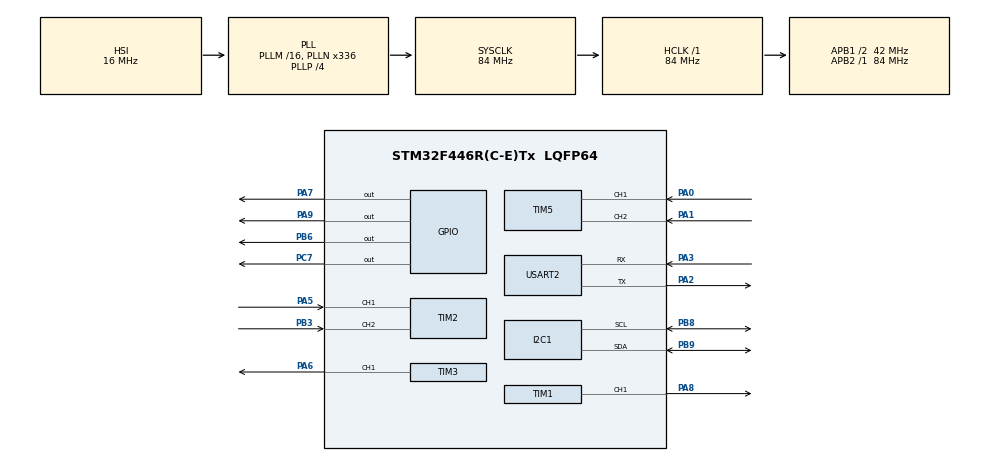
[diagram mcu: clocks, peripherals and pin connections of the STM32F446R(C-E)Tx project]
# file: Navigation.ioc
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Dma.Request0=TIM1_CH1
Dma.TIM1_CH1.0.Direction=DMA_MEMORY_TO_PERIPH
Dma.TIM1_CH1.0.FIFOMode=DMA_FIFOMODE_DISABLE
Dma.TIM1_CH1.0.Instance=DMA2_Stream1
Dma.TIM1_CH1.0.MemDataAlignment=DMA_MDATAALIGN_HALFWORD
Dma.TIM1_CH1.0.MemInc=DMA_MINC_ENABLE
Dma.TIM1_CH1.0.Mode=DMA_NORMAL
Dma.TIM1_CH1.0.PeriphDataAlignment=DMA_PDATAALIGN_HALFWORD
Dma.TIM1_CH1.0.PeriphInc=DMA_PINC_DISABLE
Dma.TIM1_CH1.0.Priority=DMA_PRIORITY_LOW
Mcu.Family=STM32F4
Mcu.Name=STM32F446R(C-E)Tx
Mcu.Package=LQFP64
NVIC.DMA2_Stream1_IRQn=true\:0\:0\:false\:false\:true\:false\:true\:true
NVIC.PriorityGroup=NVIC_PRIORITYGROUP_0
NVIC.TIM2_IRQn=true\:0\:0\:false\:false\:true\:true\:true\:true
NVIC.TIM3_IRQn=true\:0\:0\:false\:false\:true\:true\:true\:true
NVIC.TIM5_IRQn=true\:0\:0\:false\:false\:true\:true\:true\:true
PA0-WKUP.Signal=S_TIM5_CH1
PA1.Signal=S_TIM5_CH2
PA2.Mode=Asynchronous
PA2.Signal=USART2_TX
PA3.Mode=Asynchronous
PA3.Signal=USART2_RX
PA5.Signal=S_TIM2_CH1_ETR
PA6.Signal=S_TIM3_CH1
PA7.Signal=GPIO_Output
PA8.Signal=S_TIM1_CH1
PA9.Signal=GPIO_Output
PB3.Signal=S_TIM2_CH2
PB6.Signal=GPIO_Output
PB8.Mode=I2C
PB8.Signal=I2C1_SCL
PB9.Mode=I2C
PB9.Signal=I2C1_SDA
PC7.Signal=GPIO_Output
ProjectManager.HeapSize=0x200
ProjectManager.StackSize=0x400
ProjectManager.TargetToolchain=STM32CubeIDE
RCC.48MHZClocksFreq_Value=84000000
RCC.AHBFreq_Value=84000000
RCC.APB1CLKDivider=RCC_HCLK_DIV2
RCC.APB1Freq_Value=42000000
RCC.APB1TimFreq_Value=84000000
RCC.APB2Freq_Value=84000000
RCC.APB2TimFreq_Value=84000000
RCC.CortexFreq_Value=84000000
RCC.FLatency-AdvancedSettings=FLASH_LATENCY_2
RCC.HCLKFreq_Value=84000000
RCC.HSE_VALUE=8000000
RCC.HSI_VALUE=16000000
RCC.PLLN=336
RCC.PLLP=RCC_PLLP_DIV4
RCC.SYSCLKFreq_VALUE=84000000
RCC.SYSCLKSource=RCC_SYSCLKSOURCE_PLLCLK
RCC.USBFreq_Value=168000000
RCC.VCOOutputFreq_Value=336000000
SH.S_TIM1_CH1.0=TIM1_CH1,PWM Generation1 CH1
SH.S_TIM2_CH1_ETR.0=TIM2_CH1,Encoder_Interface
SH.S_TIM2_CH2.0=TIM2_CH2,Encoder_Interface
SH.S_TIM3_CH1.0=TIM3_CH1,PWM Generation1 CH1
SH.S_TIM5_CH1.0=TIM5_CH1,Encoder_Interface
SH.S_TIM5_CH2.0=TIM5_CH2,Encoder_Interface
TIM1.Channel-PWM\ Generation1\ CH1=TIM_CHANNEL_1
TIM1.Period=100-1
TIM1.Prescaler=42-1
TIM2.EncoderMode=TIM_ENCODERMODE_TI12
TIM2.IC1Polarity=TIM_ICPOLARITY_FALLING
TIM3.Channel-PWM\ Generation1\ CH1=TIM_CHANNEL_1
TIM3.Period=100-1
TIM3.Prescaler=42-1
TIM5.EncoderMode=TIM_ENCODERMODE_TI12
TIM5.IC2Polarity=TIM_ICPOLARITY_FALLING
USART2.VirtualMode=VM_ASYNC
VP_TIM1_VS_ClockSourceINT.Mode=Internal
VP_TIM3_VS_ClockSourceINT.Mode=Internal
board=NUCLEO-F446RE

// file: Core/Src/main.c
/* USER CODE BEGIN Header */
/**
  ******************************************************************************
  * @file           : main.c
  * @brief          : Main program body
  ******************************************************************************
  * @attention
  *
  * Copyright (c) 2025 STMicroelectronics.
  * All rights reserved.
  *
  * This software is licensed under terms that can be found in the LICENSE file
  * in the root directory of this software component.
  * If no LICENSE file comes with this software, it is provided AS-IS.
  *
  ******************************************************************************
  */
/* USER CODE END Header */
#include "main.h"

/* USER CODE BEGIN Includes */
#include "logic.hpp"
/* USER CODE END Includes */

I2C_HandleTypeDef hi2c1;

TIM_HandleTypeDef htim1;
TIM_HandleTypeDef htim2;
TIM_HandleTypeDef htim3;
TIM_HandleTypeDef htim5;
DMA_HandleTypeDef hdma_tim1_ch1;

UART_HandleTypeDef huart2;

/* USER CODE BEGIN PV */
void moveForward(void);
/* USER CODE END PV */

void SystemClock_Config(void);
static void MX_GPIO_Init(void);
static void MX_DMA_Init(void);
static void MX_TIM1_Init(void);
static void MX_TIM2_Init(void);
static void MX_TIM5_Init(void);
static void MX_TIM3_Init(void);
static void MX_I2C1_Init(void);
static void MX_USART2_UART_Init(void);

int main(void)
{

  /* MCU Configuration--------------------------------------------------------*/

  /* Reset of all peripherals, Initializes the Flash interface and the Systick. */
  HAL_Init();

  /* Configure the system clock */
  SystemClock_Config();

  /* Initialize all configured peripherals */
  MX_GPIO_Init();
  MX_DMA_Init();
  MX_TIM1_Init();
  MX_TIM2_Init();
  MX_TIM5_Init();
  MX_TIM3_Init();
  MX_I2C1_Init();
  MX_USART2_UART_Init();
  /* USER CODE BEGIN 2 */
  HAL_TIM_Encoder_Start_IT(&htim2, TIM_CHANNEL_ALL);
  HAL_TIM_Encoder_Start_IT(&htim5, TIM_CHANNEL_ALL);
  __HAL_TIM_ENABLE_IT(&htim2, TIM_IT_UPDATE);
  __HAL_TIM_ENABLE_IT(&htim5, TIM_IT_UPDATE);

  HAL_Delay(2000);
  robotLoop();

  /* USER CODE END 2 */

  /* Infinite loop */
  while (1)
  {

  }
}

void SystemClock_Config(void)
{
  RCC_OscInitTypeDef RCC_OscInitStruct = {0};
  RCC_ClkInitTypeDef RCC_ClkInitStruct = {0};

  /** Configure the main internal regulator output voltage
  */
  __HAL_RCC_PWR_CLK_ENABLE();
  __HAL_PWR_VOLTAGESCALING_CONFIG(PWR_REGULATOR_VOLTAGE_SCALE3);

  /** Initializes the RCC Oscillators according to the specified parameters
  * in the RCC_OscInitTypeDef structure.
  */
  RCC_OscInitStruct.OscillatorType = RCC_OSCILLATORTYPE_HSI;
  RCC_OscInitStruct.HSIState = RCC_HSI_ON;
  RCC_OscInitStruct.HSICalibrationValue = RCC_HSICALIBRATION_DEFAULT;
  RCC_OscInitStruct.PLL.PLLState = RCC_PLL_ON;
  RCC_OscInitStruct.PLL.PLLSource = RCC_PLLSOURCE_HSI;
  RCC_OscInitStruct.PLL.PLLM = 16;
  RCC_OscInitStruct.PLL.PLLN = 336;
  RCC_OscInitStruct.PLL.PLLP = RCC_PLLP_DIV4;
  RCC_OscInitStruct.PLL.PLLQ = 2;
  RCC_OscInitStruct.PLL.PLLR = 2;
  if (HAL_RCC_OscConfig(&RCC_OscInitStruct) != HAL_OK)
  {
    Error_Handler();
  }

  /** Initializes the CPU, AHB and APB buses clocks
  */
  RCC_ClkInitStruct.ClockType = RCC_CLOCKTYPE_HCLK|RCC_CLOCKTYPE_SYSCLK
                              |RCC_CLOCKTYPE_PCLK1|RCC_CLOCKTYPE_PCLK2;
  RCC_ClkInitStruct.SYSCLKSource = RCC_SYSCLKSOURCE_PLLCLK;
  RCC_ClkInitStruct.AHBCLKDivider = RCC_SYSCLK_DIV1;
  RCC_ClkInitStruct.APB1CLKDivider = RCC_HCLK_DIV2;
  RCC_ClkInitStruct.APB2CLKDivider = RCC_HCLK_DIV1;

  if (HAL_RCC_ClockConfig(&RCC_ClkInitStruct, FLASH_LATENCY_2) != HAL_OK)
  {
    Error_Handler();
  }
}

static void MX_I2C1_Init(void)
{

  hi2c1.Instance = I2C1;
  hi2c1.Init.ClockSpeed = 100000;
  hi2c1.Init.DutyCycle = I2C_DUTYCYCLE_2;
  hi2c1.Init.OwnAddress1 = 0;
  hi2c1.Init.AddressingMode = I2C_ADDRESSINGMODE_7BIT;
  hi2c1.Init.DualAddressMode = I2C_DUALADDRESS_DISABLE;
  hi2c1.Init.OwnAddress2 = 0;
  hi2c1.Init.GeneralCallMode = I2C_GENERALCALL_DISABLE;
  hi2c1.Init.NoStretchMode = I2C_NOSTRETCH_DISABLE;
  if (HAL_I2C_Init(&hi2c1) != HAL_OK)
  {
    Error_Handler();
  }

}

static void MX_TIM1_Init(void)
{

  TIM_ClockConfigTypeDef sClockSourceConfig = {0};
  TIM_MasterConfigTypeDef sMasterConfig = {0};
  TIM_OC_InitTypeDef sConfigOC = {0};
  TIM_BreakDeadTimeConfigTypeDef sBreakDeadTimeConfig = {0};

  htim1.Instance = TIM1;
  htim1.Init.Prescaler = 42-1;
  htim1.Init.CounterMode = TIM_COUNTERMODE_UP;
  htim1.Init.Period = 100-1;
  htim1.Init.ClockDivision = TIM_CLOCKDIVISION_DIV1;
  htim1.Init.RepetitionCounter = 0;
  htim1.Init.AutoReloadPreload = TIM_AUTORELOAD_PRELOAD_DISABLE;
  if (HAL_TIM_Base_Init(&htim1) != HAL_OK)
  {
    Error_Handler();
  }
  sClockSourceConfig.ClockSource = TIM_CLOCKSOURCE_INTERNAL;
  if (HAL_TIM_ConfigClockSource(&htim1, &sClockSourceConfig) != HAL_OK)
  {
    Error_Handler();
  }
  if (HAL_TIM_PWM_Init(&htim1) != HAL_OK)
  {
    Error_Handler();
  }
  sMasterConfig.MasterOutputTrigger = TIM_TRGO_RESET;
  sMasterConfig.MasterSlaveMode = TIM_MASTERSLAVEMODE_DISABLE;
  if (HAL_TIMEx_MasterConfigSynchronization(&htim1, &sMasterConfig) != HAL_OK)
  {
    Error_Handler();
  }
  sConfigOC.OCMode = TIM_OCMODE_PWM1;
  sConfigOC.Pulse = 0;
  sConfigOC.OCPolarity = TIM_OCPOLARITY_HIGH;
  sConfigOC.OCNPolarity = TIM_OCNPOLARITY_HIGH;
  sConfigOC.OCFastMode = TIM_OCFAST_DISABLE;
  sConfigOC.OCIdleState = TIM_OCIDLESTATE_RESET;
  sConfigOC.OCNIdleState = TIM_OCNIDLESTATE_RESET;
  if (HAL_TIM_PWM_ConfigChannel(&htim1, &sConfigOC, TIM_CHANNEL_1) != HAL_OK)
  {
    Error_Handler();
  }
  sBreakDeadTimeConfig.OffStateRunMode = TIM_OSSR_DISABLE;
  sBreakDeadTimeConfig.OffStateIDLEMode = TIM_OSSI_DISABLE;
  sBreakDeadTimeConfig.LockLevel = TIM_LOCKLEVEL_OFF;
  sBreakDeadTimeConfig.DeadTime = 0;
  sBreakDeadTimeConfig.BreakState = TIM_BREAK_DISABLE;
  sBreakDeadTimeConfig.BreakPolarity = TIM_BREAKPOLARITY_HIGH;
  sBreakDeadTimeConfig.AutomaticOutput = TIM_AUTOMATICOUTPUT_DISABLE;
  if (HAL_TIMEx_ConfigBreakDeadTime(&htim1, &sBreakDeadTimeConfig) != HAL_OK)
  {
    Error_Handler();
  }
  HAL_TIM_MspPostInit(&htim1);

}

static void MX_TIM2_Init(void)
{

  TIM_Encoder_InitTypeDef sConfig = {0};
  TIM_MasterConfigTypeDef sMasterConfig = {0};

  htim2.Instance = TIM2;
  htim2.Init.Prescaler = 0;
  htim2.Init.CounterMode = TIM_COUNTERMODE_UP;
  htim2.Init.Period = 4294967295;
  htim2.Init.ClockDivision = TIM_CLOCKDIVISION_DIV1;
  htim2.Init.AutoReloadPreload = TIM_AUTORELOAD_PRELOAD_DISABLE;
  sConfig.EncoderMode = TIM_ENCODERMODE_TI12;
  sConfig.IC1Polarity = TIM_ICPOLARITY_FALLING;
  sConfig.IC1Selection = TIM_ICSELECTION_DIRECTTI;
  sConfig.IC1Prescaler = TIM_ICPSC_DIV1;
  sConfig.IC1Filter = 0;
  sConfig.IC2Polarity = TIM_ICPOLARITY_RISING;
  sConfig.IC2Selection = TIM_ICSELECTION_DIRECTTI;
  sConfig.IC2Prescaler = TIM_ICPSC_DIV1;
  sConfig.IC2Filter = 0;
  if (HAL_TIM_Encoder_Init(&htim2, &sConfig) != HAL_OK)
  {
    Error_Handler();
  }
  sMasterConfig.MasterOutputTrigger = TIM_TRGO_RESET;
  sMasterConfig.MasterSlaveMode = TIM_MASTERSLAVEMODE_DISABLE;
  if (HAL_TIMEx_MasterConfigSynchronization(&htim2, &sMasterConfig) != HAL_OK)
  {
    Error_Handler();
  }

}

static void MX_TIM3_Init(void)
{

  TIM_ClockConfigTypeDef sClockSourceConfig = {0};
  TIM_MasterConfigTypeDef sMasterConfig = {0};
  TIM_OC_InitTypeDef sConfigOC = {0};

  htim3.Instance = TIM3;
  htim3.Init.Prescaler = 42-1;
  htim3.Init.CounterMode = TIM_COUNTERMODE_UP;
  htim3.Init.Period = 100-1;
  htim3.Init.ClockDivision = TIM_CLOCKDIVISION_DIV1;
  htim3.Init.AutoReloadPreload = TIM_AUTORELOAD_PRELOAD_DISABLE;
  if (HAL_TIM_Base_Init(&htim3) != HAL_OK)
  {
    Error_Handler();
  }
  sClockSourceConfig.ClockSource = TIM_CLOCKSOURCE_INTERNAL;
  if (HAL_TIM_ConfigClockSource(&htim3, &sClockSourceConfig) != HAL_OK)
  {
    Error_Handler();
  }
  if (HAL_TIM_PWM_Init(&htim3) != HAL_OK)
  {
    Error_Handler();
  }
  sMasterConfig.MasterOutputTrigger = TIM_TRGO_RESET;
  sMasterConfig.MasterSlaveMode = TIM_MASTERSLAVEMODE_DISABLE;
  if (HAL_TIMEx_MasterConfigSynchronization(&htim3, &sMasterConfig) != HAL_OK)
  {
    Error_Handler();
  }
  sConfigOC.OCMode = TIM_OCMODE_PWM1;
  sConfigOC.Pulse = 0;
  sConfigOC.OCPolarity = TIM_OCPOLARITY_HIGH;
  sConfigOC.OCFastMode = TIM_OCFAST_DISABLE;
  if (HAL_TIM_PWM_ConfigChannel(&htim3, &sConfigOC, TIM_CHANNEL_1) != HAL_OK)
  {
    Error_Handler();
  }
  HAL_TIM_MspPostInit(&htim3);

}

static void MX_TIM5_Init(void)
{

  TIM_Encoder_InitTypeDef sConfig = {0};
  TIM_MasterConfigTypeDef sMasterConfig = {0};

  htim5.Instance = TIM5;
  htim5.Init.Prescaler = 0;
  htim5.Init.CounterMode = TIM_COUNTERMODE_UP;
  htim5.Init.Period = 4294967295;
  htim5.Init.ClockDivision = TIM_CLOCKDIVISION_DIV1;
  htim5.Init.AutoReloadPreload = TIM_AUTORELOAD_PRELOAD_DISABLE;
  sConfig.EncoderMode = TIM_ENCODERMODE_TI12;
  sConfig.IC1Polarity = TIM_ICPOLARITY_RISING;
  sConfig.IC1Selection = TIM_ICSELECTION_DIRECTTI;
  sConfig.IC1Prescaler = TIM_ICPSC_DIV1;
  sConfig.IC1Filter = 0;
  sConfig.IC2Polarity = TIM_ICPOLARITY_FALLING;
  sConfig.IC2Selection = TIM_ICSELECTION_DIRECTTI;
  sConfig.IC2Prescaler = TIM_ICPSC_DIV1;
  sConfig.IC2Filter = 0;
  if (HAL_TIM_Encoder_Init(&htim5, &sConfig) != HAL_OK)
  {
    Error_Handler();
  }
  sMasterConfig.MasterOutputTrigger = TIM_TRGO_RESET;
  sMasterConfig.MasterSlaveMode = TIM_MASTERSLAVEMODE_DISABLE;
  if (HAL_TIMEx_MasterConfigSynchronization(&htim5, &sMasterConfig) != HAL_OK)
  {
    Error_Handler();
  }

}

static void MX_USART2_UART_Init(void)
{

  huart2.Instance = USART2;
  huart2.Init.BaudRate = 115200;
  huart2.Init.WordLength = UART_WORDLENGTH_8B;
  huart2.Init.StopBits = UART_STOPBITS_1;
  huart2.Init.Parity = UART_PARITY_NONE;
  huart2.Init.Mode = UART_MODE_TX_RX;
  huart2.Init.HwFlowCtl = UART_HWCONTROL_NONE;
  huart2.Init.OverSampling = UART_OVERSAMPLING_16;
  if (HAL_UART_Init(&huart2) != HAL_OK)
  {
    Error_Handler();
  }

}

static void MX_DMA_Init(void)
{

  /* DMA controller clock enable */
  __HAL_RCC_DMA2_CLK_ENABLE();

  /* DMA interrupt init */
  /* DMA2_Stream1_IRQn interrupt configuration */
  HAL_NVIC_SetPriority(DMA2_Stream1_IRQn, 0, 0);
  HAL_NVIC_EnableIRQ(DMA2_Stream1_IRQn);

}

static void MX_GPIO_Init(void)
{
  GPIO_InitTypeDef GPIO_InitStruct = {0};

  /* GPIO Ports Clock Enable */
  __HAL_RCC_GPIOA_CLK_ENABLE();
  __HAL_RCC_GPIOC_CLK_ENABLE();
  __HAL_RCC_GPIOB_CLK_ENABLE();

  /*Configure GPIO pin Output Level */
  HAL_GPIO_WritePin(GPIOA, GPIO_PIN_7|GPIO_PIN_9, GPIO_PIN_RESET);

  /*Configure GPIO pin Output Level */
  HAL_GPIO_WritePin(GPIOC, GPIO_PIN_7, GPIO_PIN_RESET);

  /*Configure GPIO pin Output Level */
  HAL_GPIO_WritePin(GPIOB, GPIO_PIN_6, GPIO_PIN_RESET);

  /*Configure GPIO pins : PA7 PA9 */
  GPIO_InitStruct.Pin = GPIO_PIN_7|GPIO_PIN_9;
  GPIO_InitStruct.Mode = GPIO_MODE_OUTPUT_PP;
  GPIO_InitStruct.Pull = GPIO_NOPULL;
  GPIO_InitStruct.Speed = GPIO_SPEED_FREQ_LOW;
  HAL_GPIO_Init(GPIOA, &GPIO_InitStruct);

  /*Configure GPIO pin : PC7 */
  GPIO_InitStruct.Pin = GPIO_PIN_7;
  GPIO_InitStruct.Mode = GPIO_MODE_OUTPUT_PP;
  GPIO_InitStruct.Pull = GPIO_NOPULL;
  GPIO_InitStruct.Speed = GPIO_SPEED_FREQ_LOW;
  HAL_GPIO_Init(GPIOC, &GPIO_InitStruct);

  /*Configure GPIO pin : PB6 */
  GPIO_InitStruct.Pin = GPIO_PIN_6;
  GPIO_InitStruct.Mode = GPIO_MODE_OUTPUT_PP;
  GPIO_InitStruct.Pull = GPIO_NOPULL;
  GPIO_InitStruct.Speed = GPIO_SPEED_FREQ_LOW;
  HAL_GPIO_Init(GPIOB, &GPIO_InitStruct);

}

void Error_Handler(void)
{
  __disable_irq();
  while (1)
  {
  }
}
